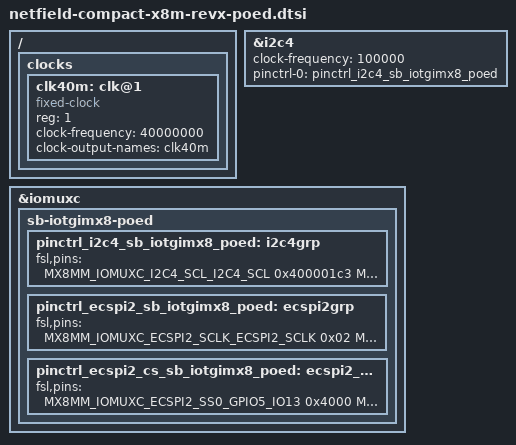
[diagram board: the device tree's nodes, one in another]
/* -------------------------------------------------------------------------- */
// NOTE:
//   Common to all Industrial I/O add-on modules

/ {
	clocks {
		#address-cells = <1>;
		#size-cells = <0>;
		clk40m: clk@1 {
			compatible = "fixed-clock";
			reg = <1>;
			#clock-cells = <0>;
			clock-frequency = <40000000>;
			clock-output-names = "clk40m";
		};
	};
};

&i2c4 {
	clock-frequency = <100000>;
	pinctrl-names = "default";
	pinctrl-0 = <&pinctrl_i2c4_sb_iotgimx8_poed>;
	status = "okay";

	// NOTE: The device nodes pca9555@22 and eeprom@54 (module detection) are created manually by platform_init script.
};

/* -------------------------------------------------------------------------- */
// NOTE:
//   Required by the Industrial I/O add-on modules (see: sb-iotgimx8-poed.dts).
//   The add-on modules themselves are activated via dt overlays.

&iomuxc {
	sb-iotgimx8-poed {
		pinctrl_i2c4_sb_iotgimx8_poed: i2c4grp {
			fsl,pins = <
				MX8MM_IOMUXC_I2C4_SCL_I2C4_SCL		0x400001c3
				MX8MM_IOMUXC_I2C4_SDA_I2C4_SDA		0x400001c3
			>;
		};

		pinctrl_ecspi2_sb_iotgimx8_poed: ecspi2grp {
			fsl,pins = <
				MX8MM_IOMUXC_ECSPI2_SCLK_ECSPI2_SCLK	0x02
				MX8MM_IOMUXC_ECSPI2_MOSI_ECSPI2_MOSI	0x02
				MX8MM_IOMUXC_ECSPI2_MISO_ECSPI2_MISO	0x102
			>;
		};

		pinctrl_ecspi2_cs_sb_iotgimx8_poed: ecspi2_csgrp {
			fsl,pins = <
				MX8MM_IOMUXC_ECSPI2_SS0_GPIO5_IO13	0x4000
				MX8MM_IOMUXC_NAND_CE0_B_GPIO3_IO1	0x04146
			>;
		};
	};
};
